# RL6842_IP_SVD register map
Vendor: Realtek
Registers are 32-bit, read-write, reset 0x0 unless marked. A register's access mark holds for its fields unless they carry their own. Offsets are from the block's base; [hi:lo] are bit positions; <NAME> marks a mode.

## AUD_SYS_REG
Base 0x41022100
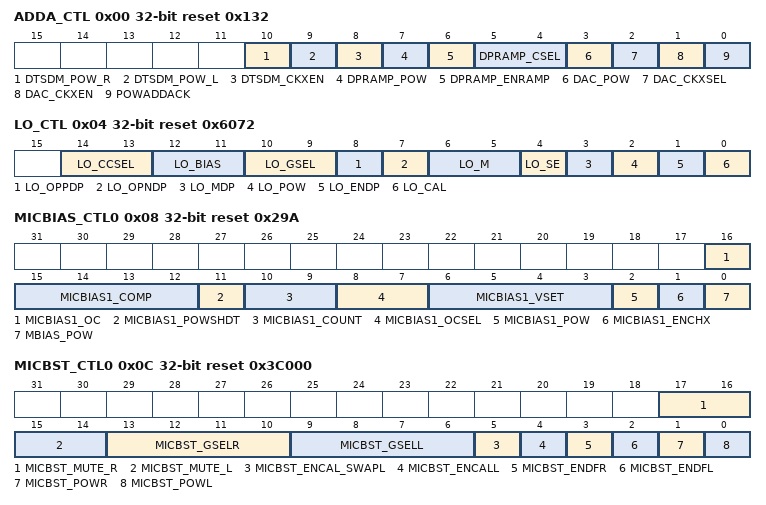
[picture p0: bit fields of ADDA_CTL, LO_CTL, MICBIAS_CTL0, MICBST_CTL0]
0x00 ADDA_CTL reset 0x132 — ADC And DAC Control Register
  [10] DTSDM_POW_R — Right channel ADC power on control 0: power down 1: power on
  [9] DTSDM_POW_L — Left channel ADC power on control 0: power down 1: power on
  [8] DTSDM_CKXEN — ADC integrater 1 OP chopper enable 0: disable 1: enable
  [7] DPRAMP_POW — DPRAMP power down control 0: power down 1: power on
  [6] DPRAMP_ENRAMP — DPRAMP enable ramp control 0: disable 1: enable
  [5:4] DPRAMP_CSEL — Depop C size selection 00: 1x 01: 2x 10: 3x 11: 4x
  [3] DAC_POW — DAC power down control 0: power down 1: power on
  [2] DAC_CKXSEL — DAC chopper clock selection 0: ckx2/4 1: ckx2/8
  [1] DAC_CKXEN — DAC chopper clock enable control 0: disable 1: enable
  [0] POWADDACK — AD/DA clock power down control 0: power down 1: power on
0x04 LO_CTL reset 0x6072 — Lineout Control Register
  [14:13] LO_CCSEL — Lineout op 1st stage miller cap size 00: 20pF 01: 24pF 10: 28pF 11: 32pF
  [12:11] LO_BIAS — Lineout mode output MOS quiescent current tuning 00: 120uA
  [10:9] LO_GSEL — Lineout gain selection 00: 0dB 01: -3dB 10: -6dB 11: -9dB
  [8] LO_OPPDP — Lineout op positive depop mode control 0: no depop 1: depop
  [7] LO_OPNDP — Lineout op negative depop mode control 0: no depop 1: depop
  [6:5] LO_M — Lineout mute control 0: un-mute 1: mute <0>: DAC <1>: Analog in
  [4] LO_SE — Lineout single-end mode control 0: differential 1: single-ended
  [3] LO_MDP — Lineout mute depop mode control 0: no depop 1: depop
  [2] LO_POW — Lineout power down control 0: power down 1: power on
  [1] LO_ENDP — Lineout enable depop control 0: disable 1: enable
  [0] LO_CAL — Lineout output offset calibration mode selection 1: calibration mode 0: normal mode
0x08 MICBIAS_CTL0 access per field reset 0x29A — MICBIAS Control Register 0
  [16] MICBIAS1_OC ro — OCP happen output signal
  [15:12] MICBIAS1_COMP rw — Bit[12]: 0: disable internal miller cap 1: enable internal miller cap Bit[15:13]: reserved
  [11] MICBIAS1_POWSHDT rw — MICBIAS OCP power control 0: disable OCP 1: enable OCP
  [10:9] MICBIAS1_COUNT rw — when OCP happen disable time @312.5kHz 00: 819.2us 01: 1638.4us 10: 3276.8us 11: 6553.6us
  [8:7] MICBIAS1_OCSEL rw — OCP current selection 00: 2.5mA 01: 5mA 10: 7.5mA 11: 10mA
  [6:3] MICBIAS1_VSET rw — MICBIAS select output voltage level, 0.1V per step 0000:1.15V 0001:1.25V 0010:1.35V 0011:1.45V 0100:1.55V 0101:1.65V 0110:1.75V 0111:1.8V
  [2] MICBIAS1_POW rw — MICBIAS power control 0: power down 1: power on
  [1] MICBIAS1_ENCHX rw — MICBIAS enable chopper clock 0: disable 1: enable
  [0] MBIAS_POW rw — MBIAS power control 0: power down 1: power on
0x0C MICBST_CTL0 reset 0x3C000 — MICBST Control Register 0
  [17:16] MICBST_MUTE_R — MICBST right channel mute control mute<0>: mic in mute<1>: line in 0: unmute 1: mute
  [15:14] MICBST_MUTE_L — MICBST left channel mute control mute<0>: mic in mute<1>: line in 0: unmute 1: mute
  [13:10] MICBST_GSELR — MICBST right channel gain select 0000: 0dB 0001: 5dB 0010: 10dB 0011: 15dB 0100: 20dB 0101: 25dB 0110: 30dB 0111: 35dB 1XXX: 40dB
  [9:6] MICBST_GSELL — MICBST left channel gain select 0000: 0dB 0001: 5dB 0010: 10dB 0011: 15dB 0100: 20dB 0101: 25dB 0110: 30dB 0111: 35dB 1XXX: 40dB
  [5] MICBST_ENCAL_SWAPL — MICBST left channel swap calibration path 0: disable 1: enable
  [4] MICBST_ENCALL — MICBST left channel enable calibration path 0: disable 1: enable
  [3] MICBST_ENDFR — MICBST right channel enable differential 0: single to differential 1: differential to differential
  [2] MICBST_ENDFL — MICBST left channel enable differential 0: single to differential 1: differential to differential
  [1] MICBST_POWR — MICBST power control, right channel 0: power down 1: power on
  [0] MICBST_POWL — MICBST power control, left channel 0: power down 1: power on
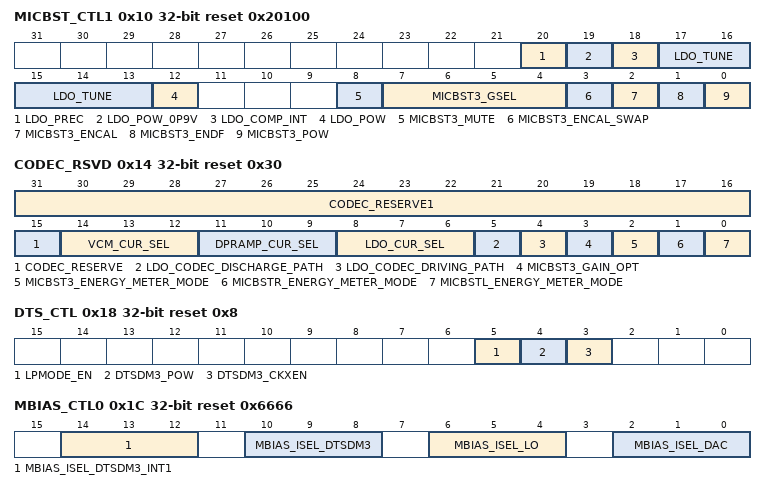
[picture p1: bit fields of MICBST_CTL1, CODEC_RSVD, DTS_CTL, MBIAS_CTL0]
0x10 MICBST_CTL1 reset 0x20100 — MICBST Control Register 1
  [20] LDO_PREC — LOD_PREC
  [19] LDO_POW_0P9V — LDO precharge 0: LDO 1: Unity gain buffer
  [18] LDO_COMP_INT — LDO miller compensation 0: close 1: short
  [17:13] LDO_TUNE — LDO voltage control 10000: Vref 0.9V, LDO 1.8V
  [12] LDO_POW — LDO power control 0: disable LDO 1: enable LDO
  [8] MICBST3_MUTE — MICBST3 mute control mute: mic in 0: unmute 1: mute
  [7:4] MICBST3_GSEL — MICBST3 channel gain select If CODEC_RESERVE<3>=0 (MICBST3_GAIN_OPT=0) 0000: 3.52 dB 0001: 7.23 dB 0010: 11.36 dB 0011: 15.85 dB 0100: 20.42 dB 0101: 25.34 dB 0110: 31.25 dB 0111: 35.19 dB 1XXX: 40.04 dB If CODEC_RESERVE<3>=1 (MICBST3_GAIN_OPT=1) 0000: 3.52 dB 0001: 7.23 dB 0010: 11.36 dB 0011: 15.85 dB 0100: 20.42 dB 0101: 25.34 dB 0110: 25.34 dB 0111: 29.25 dB 1XXX: 34.07 dB
  [3] MICBST3_ENCAL_SWAP — MICBST3 swap calibration path 0: disable 1: enable
  [2] MICBST3_ENCAL — MICBST3 enable calibration path 0: disable 1: enable
  [1] MICBST3_ENDF — MICBST3 channel enable differential 0: single to differential 1: differential to differential
  [0] MICBST3_POW — MICBST3 power control, left channel 0: power down 1: power on
0x14 CODEC_RSVD reset 0x30 — CODEC Reserved Register
  [31:16] CODEC_RESERVE1 — Reserved
  [15] CODEC_RESERVE — Reserved
  [14:12] VCM_CUR_SEL — DAC VCM buffer current control: If LPMODE_EN=1: 000: 1uA 001: 1.5uA 010: 2uA 011: 2.5uA 100: 3uA 101: 3.5uA 110: 4uA 111: 4.5uA If LPMODE_EN=0: 000: 2uA 001: 3uA 010: 4uA 011: 5uA 100: 6uA 101: 7uA 110: 8uA 111: 9uA
  [11:9] DPRAMP_CUR_SEL — DPRAMP current control: If LPMODE_EN=1: 000: 1uA 001: 1.5uA 010: 2uA 011: 2.5uA 100: 3uA 101: 3.5uA 110: 4uA 111: 4.5uA If LPMODE_EN=0: 000: 2uA 001: 3uA 010: 4uA 011: 5uA 100: 6uA 101: 7uA 110: 8uA 111: 9uA
  [8:6] LDO_CUR_SEL — LDO current control If LPMODE_EN=1: 000: 1uA 001: 1.5uA 010: 2uA 011: 2.5uA 100: 3uA 101: 3.5uA 110: 4uA 111: 4.5uA If LPMODE_EN=0: 000: 2uA 001: 3uA 010: 4uA 011: 5uA 100: 6uA 101: 7uA 110: 8uA 111: 9uA
  [5] LDO_CODEC_DISCHARGE_PATH — Selection for discharge path of LDO_CODEC 0: discharge path is turned off 1: 1.8kohm discharge path is turned on
  [4] LDO_CODEC_DRIVING_PATH — Selection for driving path of LDO_CODEC 0: select strong driving path, PMOS W=240um, L=0.44um 1: select 1.8kohm driving path
  [3] MICBST3_GAIN_OPT — Influence gain of MICBST3, see MICBST3_GSEL
  [2] MICBST3_ENERGY_METER_MODE — 0: turn off energy-meter mode of MICBST3 1: turn on energy-meter mode of MICBST3
  [1] MICBSTR_ENERGY_METER_MODE — 0: turn off energy-meter mode of MICBST_R 1: turn on energy-meter mode of MICBST_R
  [0] MICBSTL_ENERGY_METER_MODE — 0: turn off energy-meter mode of MICBST_L 1: turn on energy-meter mode of MICBST_L
0x18 DTS_CTL reset 0x8 — DTS Control Register
  [5] LPMODE_EN — low power mode enable 0: disable, current uses 12.5uA 1: enable, current uses 1uA
  [4] DTSDM3_POW — Left channel ADC power on control 0: power down 1: power on
  [3] DTSDM3_CKXEN — ADC integrater 1 OP chopper enable 0: disable 1: enable
0x1C MBIAS_CTL0 reset 0x6666 — MBIAS Control Register 0
  [14:12] MBIAS_ISEL_DTSDM3_INT1 — DTSDM3 integrator current control If LPMODE_EN=1: 000: 2uA 001: 3uA 010: 4uA 011: 5uA 100: 6uA 101: 7uA 110: 8uA 111: 9uA If LPMODE_EN=0: 000: 4uA 001: 6uA 010: 8uA 011: 10uA 100: 12uA 101: 14uA 110: 16uA 111: 18uA
  [10:8] MBIAS_ISEL_DTSDM3 — DTSDM3 current control If LPMODE_EN=1: 000: 1uA 001: 1.5uA 010: 2uA 011: 2.5uA 100: 3uA 101: 3.5uA 110: 4uA 111: 4.5uA If LPMODE_EN=0: 000: 2uA 001: 3uA 010: 4uA 011: 5uA 100: 6uA 101: 7uA 110: 8uA 111: 9uA
  [6:4] MBIAS_ISEL_LO — Lineout current control If LPMODE_EN=1: 000: 1uA 001: 1.5uA 010: 2uA 011: 2.5uA 100: 3uA 101: 3.5uA 110: 4uA 111: 4.5uA If LPMODE_EN=0: 000: 2uA 001: 3uA 010: 4uA 011: 5uA 100: 6uA 101: 7uA 110: 8uA 111: 9uA
  [2:0] MBIAS_ISEL_DAC — DAC current control If LPMODE_EN=1: 000: 1uA 001: 1.5uA 010: 2uA 011: 2.5uA 100: 3uA 101: 3.5uA 110: 4uA 111: 4.5uA If LPMODE_EN=0: 000: 2uA 001: 3uA 010: 4uA 011: 5uA 100: 6uA 101: 7uA 110: 8uA 111: 9uA
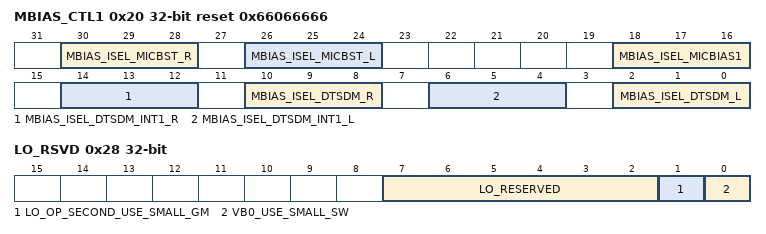
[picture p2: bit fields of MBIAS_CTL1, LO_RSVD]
0x20 MBIAS_CTL1 reset 0x66066666 — MBIAS Control Register 1
  [30:28] MBIAS_ISEL_MICBST_R — MICBST_R current control If LPMODE_EN=1 If LPMODE_EN=1: 000: 1uA 001: 1.5uA 010: 2uA 011: 2.5uA 100: 3uA 101: 3.5uA 110: 4uA 111: 4.5uA If LPMODE_EN=0: 000: 2uA 001: 3uA 010: 4uA 011: 5uA 100: 6uA 101: 7uA 110: 8uA 111: 9uA
  [26:24] MBIAS_ISEL_MICBST_L — MICBST_L current control If LPMODE_EN=1: 000: 1uA 001: 1.5uA 010: 2uA 011: 2.5uA 100: 3uA 101: 3.5uA 110: 4uA 111: 4.5uA If LPMODE_EN=0: 000: 2uA 001: 3uA 010: 4uA 011: 5uA 100: 6uA 101: 7uA 110: 8uA 111: 9uA
  [18:16] MBIAS_ISEL_MICBIAS1 — MICBIAS1 current control If LPMODE_EN=1: 000: 1uA 001: 1.5uA 010: 2uA 011: 2.5uA 100: 3uA 101: 3.5uA 110: 4uA 111: 4.5uA If LPMODE_EN=0: 000: 2uA 001: 3uA 010: 4uA 011: 5uA 100: 6uA 101: 7uA 110: 8uA 111: 9uA
  [14:12] MBIAS_ISEL_DTSDM_INT1_R — DTSDM1_R integrator current control If LPMODE_EN=1: 000: 2uA 001: 3uA 010: 4uA 011: 5uA 100: 6uA 101: 7uA 110: 8uA 111: 9uA If LPMODE_EN=0: 000: 4uA 001: 6uA 010: 8uA 011: 10uA 100: 12uA 101: 14uA 110: 16uA 111: 18uA
  [10:8] MBIAS_ISEL_DTSDM_R — DTSDM1_R current control If LPMODE_EN=1: 000: 1uA 001: 1.5uA 010: 2uA 011: 2.5uA 100: 3uA 101: 3.5uA 110: 4uA 111: 4.5uA If LPMODE_EN=0: 000: 2uA 001: 3uA 010: 4uA 011: 5uA 100: 6uA 101: 7uA 110: 8uA 111: 9uA
  [6:4] MBIAS_ISEL_DTSDM_INT1_L — DTSDM1_L integrator current control If LPMODE_EN=1: 000: 2uA 001: 3uA 010: 4uA 011: 5uA 100: 6uA 101: 7uA 110: 8uA 111: 9uA If LPMODE_EN=0: 000: 4uA 001: 6uA 010: 8uA 011: 10uA 100: 12uA 101: 14uA 110: 16uA 111: 18uA
  [2:0] MBIAS_ISEL_DTSDM_L — DTSDM1_L current control If LPMODE_EN=1: 000: 1uA 001: 1.5uA 010: 2uA 011: 2.5uA 100: 3uA 101: 3.5uA 110: 4uA 111: 4.5uA If LPMODE_EN=0: 000: 2uA 001: 3uA 010: 4uA 011: 5uA 100: 6uA 101: 7uA 110: 8uA 111: 9uA
0x24 MBIAS_CTL2 reset 0x600 — MBIAS Control Register 2
  [10:8] MBIAS_ISEL_MICBST3 — MICBST3 current control If LPMODE_EN=1: 000: 1uA 001: 1.5uA 010: 2uA 011: 2.5uA 100: 3uA 101: 3.5uA 110: 4uA 111: 4.5uA If LPMODE_EN=0: 000: 2uA 001: 3uA 010: 4uA 011: 5uA 100: 6uA 101: 7uA 110: 8uA 111: 9uA
0x28 LO_RSVD — LO Reserved Register
  [7:2] LO_RESERVED — Reserved
  [1] LO_OP_SECOND_USE_SMALL_GM — 0: enlarge 2nd stage gm of LO opamp to reduce voltage stress 1: 2nd stage gm of LO opamp uses default small gm
  [0] VB0_USE_SMALL_SW — 0: use large switch to get better THD performance of Lineout 1: use small switch
0x2C AUD_DUMMY reset 0xFF
  [15:0] dummy — HW used only, reserved
